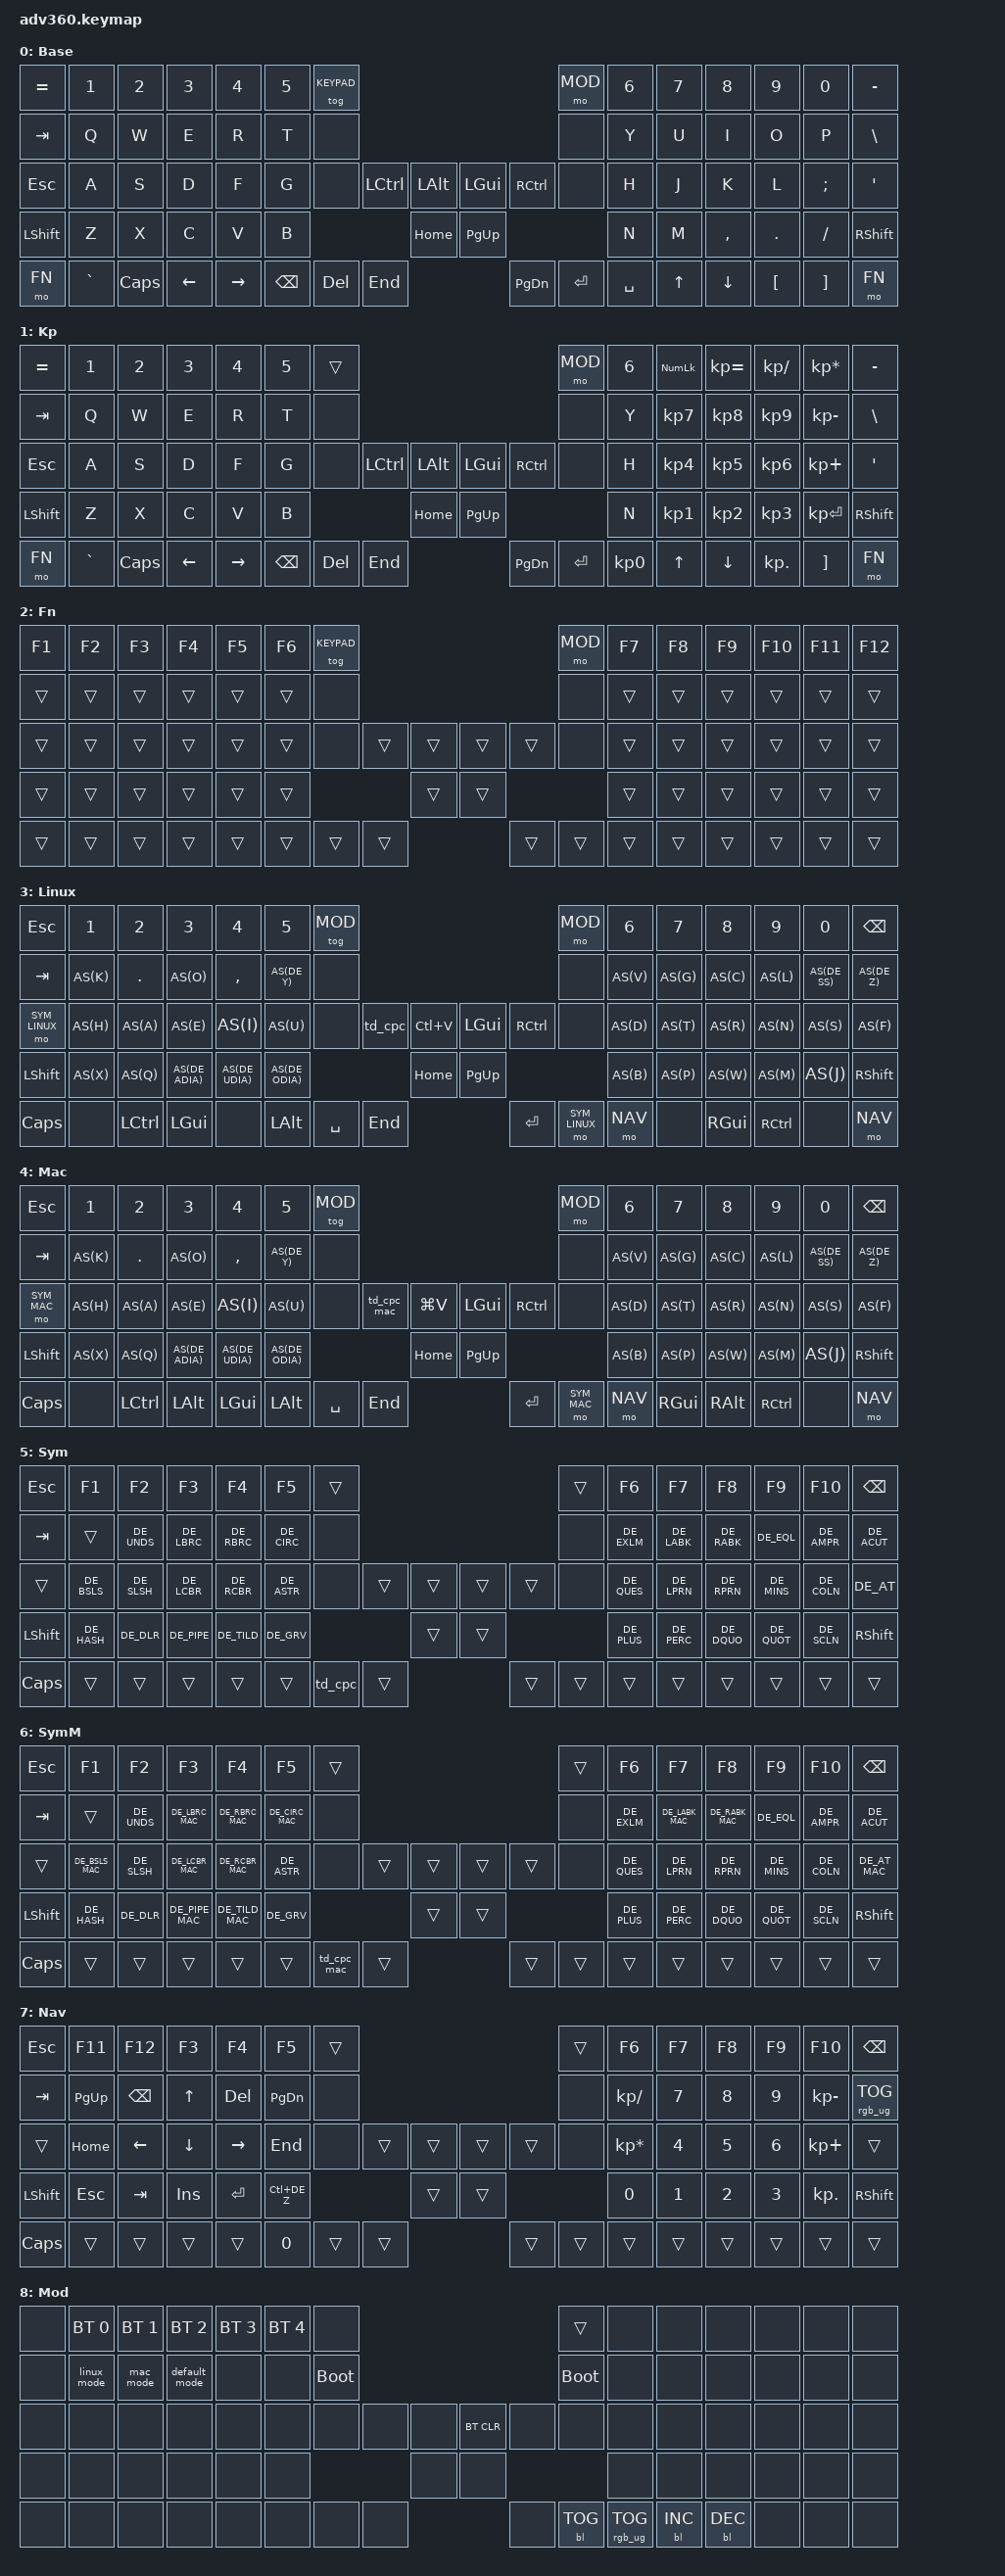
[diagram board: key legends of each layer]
#include <behaviors.dtsi>
#include <dt-bindings/zmk/keys.h>
#include <dt-bindings/zmk/bt.h>
#include <dt-bindings/zmk/rgb.h>
#include <dt-bindings/zmk/backlight.h>

// German layout aliases
#define DE_Y Z
#define DE_Z Y
#define DE_SS MINUS
#define DE_UDIA LBKT
#define DE_ODIA SEMI
#define DE_ADIA SQT
#define DE_ACUT EQUAL
#define DE_PLUS RBKT
#define DE_HASH NUHS
#define DE_LABK NUBS
#define DE_MINS SLASH
#define DE_CIRC GRAVE

#define DE_DEG LS(DE_CIRC)
#define DE_EXLM LS(N1)
#define DE_DQUO LS(N2)
#define DE_DLR LS(N4)
#define DE_PERC LS(N5)
#define DE_AMPR LS(N6)
#define DE_SLSH LS(N7)
#define DE_LPRN LS(N8)
#define DE_RPRN LS(N9)
#define DE_EQL LS(N0)
#define DE_QUES LS(DE_SS)
#define DE_GRV LS(DE_ACUT)
#define DE_ASTR LS(DE_PLUS)
#define DE_QUOT LS(DE_HASH)
#define DE_RABK LS(DE_LABK)
#define DE_SCLN LS(COMMA)
#define DE_COLN LS(DOT)
#define DE_UNDS LS(DE_MINS)

// Linux AltGr symbols
#define DE_AT RA(Q)
#define DE_LBRC RA(N8)
#define DE_RBRC RA(N9)
#define DE_LCBR RA(N7)
#define DE_RCBR RA(N0)
#define DE_BSLS RA(DE_SS)
#define DE_PIPE RA(DE_LABK)
#define DE_TILD RA(DE_PLUS)

// Mac Option symbols
#define DE_AT_MAC LA(L)
#define DE_LBRC_MAC LA(N5)
#define DE_RBRC_MAC LA(N6)
#define DE_LCBR_MAC LA(N8)
#define DE_RCBR_MAC LA(N9)
#define DE_BSLS_MAC LA(LS(N7))
#define DE_PIPE_MAC LA(N7)
#define DE_TILD_MAC LA(N)

// Mac different base keys
#define DE_LABK_MAC GRAVE
#define DE_RABK_MAC LS(GRAVE)
#define DE_CIRC_MAC NUBS
#define DE_DEG_MAC LS(NUBS)

// Layer indices
#define DEFAULT 0
#define KEYPAD 1
#define FN 2
#define BONE_LINUX 3
#define BONE_MAC 4
#define SYM_LINUX 5
#define SYM_MAC 6
#define NAV 7
#define MOD 8

// Auto-shift macros: tap = lowercase, hold = shifted
#define AS(k) &as LS(k) k

/ {
    macros {
        linux_mode: linux_mode {
            compatible = "zmk,behavior-macro";
            #binding-cells = <0>;
            bindings = <&bt BT_SEL 0>, <&to BONE_LINUX>;
        };
        mac_mode: mac_mode {
            compatible = "zmk,behavior-macro";
            #binding-cells = <0>;
            bindings = <&bt BT_SEL 1>, <&to BONE_MAC>;
        };
        default_mode: default_mode {
            compatible = "zmk,behavior-macro";
            #binding-cells = <0>;
            bindings = <&to DEFAULT>;
        };
    };

    behaviors {
        as: auto_shift {
            compatible = "zmk,behavior-hold-tap";
            #binding-cells = <2>;
            tapping-term-ms = <100>;
            quick-tap-ms = <0>;
            flavor = "tap-preferred";
            bindings = <&kp>, <&kp>;
        };
        td_cpc: tap_dance_copy_paste_cut {
            compatible = "zmk,behavior-tap-dance";
            #binding-cells = <0>;
            tapping-term-ms = <200>;
            bindings = <&kp LC(C)>, <&kp LC(X)>, <&kp LC(V)>;
        };
        td_cpc_mac: tap_dance_copy_paste_cut_mac {
            compatible = "zmk,behavior-tap-dance";
            #binding-cells = <0>;
            tapping-term-ms = <200>;
            bindings = <&kp LG(C)>, <&kp LG(X)>, <&kp LG(V)>;
        };
    };

    keymap {
        compatible = "zmk,keymap";

        // Layer 0: Stock QWERTY
        default_layer {
            display-name = "Base";
            bindings = <
                &kp EQUAL &kp N1    &kp N2   &kp N3   &kp N4     &kp N5 &tog KEYPAD                                                       &mo MOD &kp N6 &kp N7 &kp N8    &kp N9   &kp N0   &kp MINUS
                &kp TAB   &kp Q     &kp W    &kp E    &kp R      &kp T  &none                                                             &none   &kp Y  &kp U  &kp I     &kp O    &kp P    &kp BSLH
                &kp ESC   &kp A     &kp S    &kp D    &kp F      &kp G  &none           &kp LCTRL &kp LALT &kp LGUI  &kp RCTRL            &none   &kp H  &kp J  &kp K     &kp L    &kp SEMI &kp SQT
                &kp LSHFT &kp Z     &kp X    &kp C    &kp V      &kp B                            &kp HOME &kp PG_UP                              &kp N  &kp M  &kp COMMA &kp DOT  &kp FSLH &kp RSHFT
                &mo FN    &kp GRAVE &kp CAPS &kp LEFT &kp RIGHT                &kp BSPC &kp DEL   &kp END  &kp PG_DN &kp ENTER &kp SPACE                 &kp UP &kp DOWN  &kp LBKT &kp RBKT &mo FN
            >;
        };

        // Layer 1: Stock Keypad
        keypad {
            display-name = "Kp";
            bindings = <
                &kp EQUAL &kp N1    &kp N2   &kp N3   &kp N4     &kp N5 &trans                                                            &mo MOD &kp N6 &kp KP_NUM &kp KP_EQUAL &kp KP_DIVIDE &kp KP_MULTIPLY &kp MINUS
                &kp TAB   &kp Q     &kp W    &kp E    &kp R      &kp T  &none                                                             &none   &kp Y  &kp KP_N7  &kp KP_N8    &kp KP_N9     &kp KP_MINUS    &kp BSLH
                &kp ESC   &kp A     &kp S    &kp D    &kp F      &kp G  &none           &kp LCTRL &kp LALT &kp LGUI  &kp RCTRL            &none   &kp H  &kp KP_N4  &kp KP_N5    &kp KP_N6     &kp KP_PLUS     &kp SQT
                &kp LSHFT &kp Z     &kp X    &kp C    &kp V      &kp B                            &kp HOME &kp PG_UP                              &kp N  &kp KP_N1  &kp KP_N2    &kp KP_N3     &kp KP_ENTER    &kp RSHFT
                &mo FN    &kp GRAVE &kp CAPS &kp LEFT &kp RIGHT                &kp BSPC &kp DEL   &kp END  &kp PG_DN &kp ENTER &kp KP_N0                 &kp UP     &kp DOWN     &kp KP_DOT    &kp RBKT        &mo FN
            >;
        };

        // Layer 2: Stock Fn
        fn {
            display-name = "Fn";
            bindings = <
                &kp F1 &kp F2 &kp F3 &kp F4 &kp F5 &kp F6 &tog KEYPAD                                                &mo MOD &kp F7 &kp F8 &kp F9 &kp F10 &kp F11 &kp F12
                &trans &trans &trans &trans &trans &trans  &none                                                     &none   &trans &trans &trans &trans  &trans  &trans
                &trans &trans &trans &trans &trans &trans  &none        &trans &trans &trans &trans                  &none   &trans &trans &trans &trans  &trans  &trans
                &trans &trans &trans &trans &trans &trans                      &trans &trans                                 &trans &trans &trans &trans  &trans  &trans
                &trans &trans &trans &trans &trans               &trans &trans &trans &trans &trans &trans                          &trans &trans &trans  &trans  &trans
            >;
        };

        // Layer 3: Bone Linux
        bone_linux {
            display-name = "Linux";
            bindings = <
                &kp ESC   &kp N1  &kp N2     &kp N3       &kp N4       &kp N5     &tog MOD                                                                  &mo MOD &kp N6  &kp N7  &kp N8     &kp N9  &kp N0       &kp BSPC
                &kp TAB   AS(K)   &kp DOT    AS(O)        &kp COMMA    AS(DE_Y)   &none                                                                     &none   AS(V)   AS(G)   AS(C)      AS(L)   AS(DE_SS)    AS(DE_Z)
                &mo SYM_LINUX AS(H) AS(A)   AS(E)        AS(I)        AS(U)      &none             &td_cpc &kp LC(V)  &kp LGUI  &kp RCTRL                    &none   AS(D)   AS(T)   AS(R)      AS(N)   AS(S)        AS(F)
                &kp LSHFT AS(X)  AS(Q)      AS(DE_ADIA)  AS(DE_UDIA)  AS(DE_ODIA)                          &kp HOME   &kp PG_UP                                      AS(B)   AS(P)   AS(W)      AS(M)   AS(J)        &kp RSHFT
                &kp CAPS   &none  &kp LCTRL      &kp LGUI        &none                   &kp LALT &kp SPACE &kp END    &kp ENTER &mo SYM_LINUX  &mo NAV                          &none   &kp RGUI      &kp RCTRL   &none        &mo NAV
            >;
        };

        // Layer 4: Bone Mac
        bone_mac {
            display-name = "Mac";
            bindings = <
                &kp ESC   &kp N1  &kp N2     &kp N3       &kp N4       &kp N5     &tog MOD                                                                  &mo MOD &kp N6  &kp N7  &kp N8     &kp N9  &kp N0       &kp BSPC
                &kp TAB   AS(K)   &kp DOT    AS(O)        &kp COMMA    AS(DE_Y)   &none                                                                     &none   AS(V)   AS(G)   AS(C)      AS(L)   AS(DE_SS)    AS(DE_Z)
                &mo SYM_MAC AS(H) AS(A)   AS(E)        AS(I)        AS(U)      &none             &td_cpc_mac &kp LG(V)  &kp LGUI  &kp RCTRL                    &none   AS(D)   AS(T)   AS(R)      AS(N)   AS(S)        AS(F)
                &kp LSHFT AS(X)  AS(Q)      AS(DE_ADIA)  AS(DE_UDIA)  AS(DE_ODIA)                          &kp HOME   &kp PG_UP                                      AS(B)   AS(P)   AS(W)      AS(M)   AS(J)        &kp RSHFT
                &kp CAPS   &none  &kp LCTRL      &kp LALT        &kp LGUI                   &kp LALT &kp SPACE &kp END    &kp ENTER &mo SYM_MAC  &mo NAV                          &kp RGUI   &kp RALT      &kp RCTRL   &none        &mo NAV
            >;
        };

        // Layer 5: Symbols Linux
        sym_linux {
            display-name = "Sym";
            bindings = <
                &kp ESC   &kp F1      &kp F2      &kp F3      &kp F4      &kp F5 &trans                                                               &trans &kp F6      &kp F7      &kp F8      &kp F9      &kp F10     &kp BSPC
                &kp TAB   &trans      &kp DE_UNDS &kp DE_LBRC &kp DE_RBRC &kp DE_CIRC &none                                                            &none  &kp DE_EXLM &kp DE_LABK &kp DE_RABK &kp DE_EQL  &kp DE_AMPR &kp DE_ACUT
                &trans &kp DE_BSLS &kp DE_SLSH &kp DE_LCBR &kp DE_RCBR &kp DE_ASTR &none       &trans    &trans    &trans    &trans               &none  &kp DE_QUES &kp DE_LPRN &kp DE_RPRN &kp DE_MINS &kp DE_COLN &kp DE_AT
                &kp LSHFT &kp DE_HASH &kp DE_DLR  &kp DE_PIPE &kp DE_TILD &kp DE_GRV                        &trans    &trans                                &kp DE_PLUS &kp DE_PERC &kp DE_DQUO &kp DE_QUOT &kp DE_SCLN &kp RSHFT
                &kp CAPS    &trans      &trans      &trans      &trans                      &trans  &td_cpc   &trans    &trans    &trans &trans                           &trans      &trans      &trans      &trans      &trans
            >;
        };

        // Layer 6: Symbols Mac
        sym_mac {
            display-name = "SymM";
            bindings = <
                &kp ESC   &kp F1      &kp F2      &kp F3      &kp F4      &kp F5 &trans                                                               &trans &kp F6      &kp F7      &kp F8      &kp F9      &kp F10     &kp BSPC
                &kp TAB   &trans      &kp DE_UNDS &kp DE_LBRC_MAC &kp DE_RBRC_MAC &kp DE_CIRC_MAC &none                                                &none  &kp DE_EXLM &kp DE_LABK_MAC &kp DE_RABK_MAC &kp DE_EQL  &kp DE_AMPR &kp DE_ACUT
                &trans   &kp DE_BSLS_MAC &kp DE_SLSH &kp DE_LCBR_MAC &kp DE_RCBR_MAC &kp DE_ASTR &none       &trans    &trans    &trans    &trans    &none  &kp DE_QUES &kp DE_LPRN &kp DE_RPRN &kp DE_MINS &kp DE_COLN &kp DE_AT_MAC
                &kp LSHFT  &kp DE_HASH &kp DE_DLR  &kp DE_PIPE_MAC &kp DE_TILD_MAC &kp DE_GRV                        &trans    &trans                          &kp DE_PLUS &kp DE_PERC &kp DE_DQUO &kp DE_QUOT &kp DE_SCLN &kp RSHFT
                &kp CAPS    &trans      &trans      &trans      &trans                      &trans  &td_cpc_mac &trans  &trans    &trans &trans                           &trans      &trans      &trans      &trans      &trans
            >;
        };

        // Layer 7: Navigation
        nav_layer {
            display-name = "Nav";
            bindings = <
                &kp ESC   &kp F11     &kp F12  &kp F3   &kp F4    &kp F5 &trans                                                                       &trans &kp F6          &kp F7 &kp F8 &kp F9    &kp F10      &kp BSPC
                &kp TAB   &kp PG_UP   &kp BSPC &kp UP   &kp DEL   &kp PG_DN &none                                                                     &none  &kp KP_SLASH    &kp N7 &kp N8 &kp N9    &kp KP_MINUS &rgb_ug RGB_TOG
                &trans    &kp HOME    &kp LEFT &kp DOWN &kp RIGHT &kp END &none         &trans    &trans    &trans    &trans                         &none  &kp KP_ASTERISK &kp N4 &kp N5 &kp N6    &kp KP_PLUS  &trans
                &kp LSHFT   &kp ESC     &kp TAB  &kp INS  &kp ENTER &kp LC(DE_Z)                    &trans    &trans                                          &kp N0          &kp N1 &kp N2 &kp N3    &kp KP_DOT   &kp RSHFT
                &kp CAPS    &trans      &trans   &trans   &trans                    &kp N0 &trans   &trans    &trans    &trans    &trans                                      &trans &trans &trans    &trans       &trans
            >;
        };

        // Layer 8: Mod - switch between layouts
        mod_layer {
            display-name = "Mod";
            bindings = <
                &none &bt BT_SEL 0 &bt BT_SEL 1 &bt BT_SEL 2 &bt BT_SEL 3 &bt BT_SEL 4 &none                                                          &trans      &none &none      &none      &none &none &none
                &none &linux_mode  &mac_mode    &default_mode &none       &none        &bootloader                                                    &bootloader &none &none      &none      &none &none &none
                &none &none        &none        &none        &none        &none        &none             &none &none &bt BT_CLR &none                  &none       &none &none      &none      &none &none &none
                &none &none        &none        &none        &none        &none                                &none &none                                         &none &none      &none      &none &none &none
                &none &none        &none        &none        &none                               &none &none   &none &none      &bl BL_TOG &rgb_ug RGB_TOG                  &bl BL_INC &bl BL_DEC &none &none &none
            >;
        };
    };
};
